# TESTCHIP register map
Registers are 32-bit, read-write, reset 0x0 unless marked. A register's access mark holds for its fields unless they carry their own. Offsets are from the block's base; lines under a group give offsets from that group; [hi:lo] are bit positions; {n}, {i} and the like mark numbered series; 'fields as' and 'values as' point back to an identical list; <NAME> marks a mode.

## Memory map
0x40004400 UART_1
0x48000000 GPIOA — General-purpose I/O & pins
0x48000400 GPIOB

## GPIOA — General-purpose I/O & pins
Base 0x48000000
Same registers: GPIOB 0x48000400
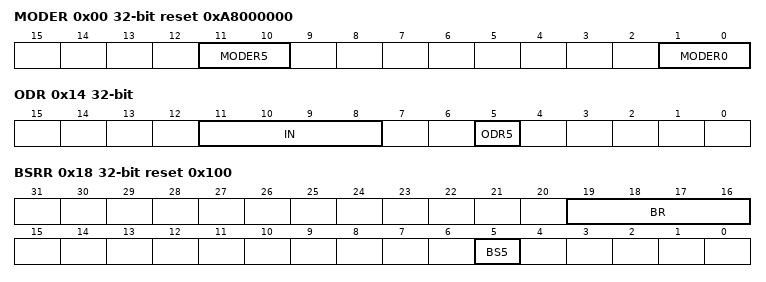
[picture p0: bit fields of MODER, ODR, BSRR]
0x00 MODER reset 0xA8000000 — Mode register.
  [11:10] MODER5, [1:0] MODER0
0x10 IDR ro
  [5] IDR5
0x14 ODR
  [11:8] IN ro — A keyword as a name
  [5] ODR5
0x18 BSRR wo reset 0x100
  [19:16] BR, [5] BS5

## UART_1
Base 0x40004400
0x04 DR 8-bit
  [7:0] DATA
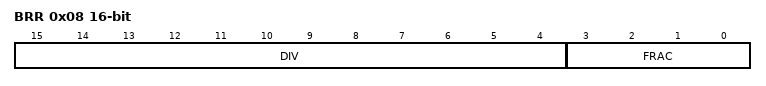
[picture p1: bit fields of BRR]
0x08 BRR 16-bit
  [15:4] DIV, [3:0] FRAC
0x10 STAMP 64-bit
  [63:32] HIGH
{0x20+4i} CH{i} (i=0..1)
  [0] EN
    0=OFF; 1=ON
0x40 FIFO group
